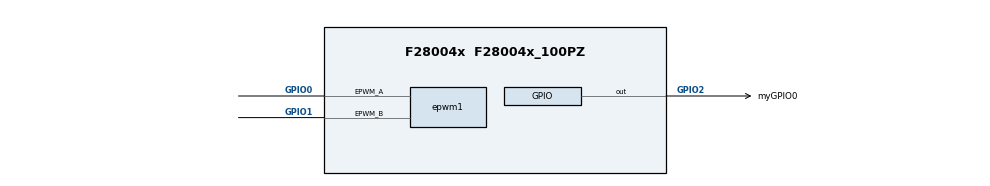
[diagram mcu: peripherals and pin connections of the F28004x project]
/**
 * @cliArgs --device "F28004x" --part "F28004x_100PZ" --package "F28004x_100PZ" --context "system" --product "C2000WARE@5.03.00.00"
 * @versions {"tool":"1.21.0+3721"}
 */

/**
 * Import the modules used in this configuration.
 */
const epwm  = scripting.addModule("/driverlib/epwm.js", {}, false);
const epwm1 = epwm.addInstance();
const gpio  = scripting.addModule("/driverlib/gpio.js", {}, false);
const gpio1 = gpio.addInstance();

/**
 * Write custom configuration values to the imported modules.
 */
epwm1.$name                                = "myEPWM0";
epwm1.epwmTimebase_counterMode             = "EPWM_COUNTER_MODE_UP_DOWN";
epwm1.epwmEventTrigger_enableInterrupt     = true;
epwm1.epwmEventTrigger_registerInterrupts  = true;
epwm1.epwmEventTrigger_interruptSource     = "EPWM_INT_TBCTR_ZERO";
epwm1.epwmEventTrigger_interruptEventCount = "1";
epwm1.epwmTimebase_period                  = 200;
epwm1.epwm.$assign                         = "EPWM1";
epwm1.epwm.epwm_aPin.$assign               = "GPIO0";
epwm1.epwm.epwm_bPin.$assign               = "GPIO1";
epwm1.epwmInt.enableInterrupt              = true;

gpio1.$name           = "myGPIO0";
gpio1.direction       = "GPIO_DIR_MODE_OUT";
gpio1.gpioPin.$assign = "GPIO2";
